# MSS_CTRL register map
Vendor: Texas Instruments
Peripheral module from a debugger description file (folder awr2544).
Registers are 32-bit, read-write, no defined reset value unless marked. A register's access mark holds for its fields unless they carry their own. Offsets are as the file gives them; lines under a group give offsets from that group; [hi:lo] are bit positions; {n}, {i} and the like mark numbered series; 'fields as' and 'values as' point back to an identical list; <NAME> marks a mode.

## MSS_CTRL (part 1 of 2)
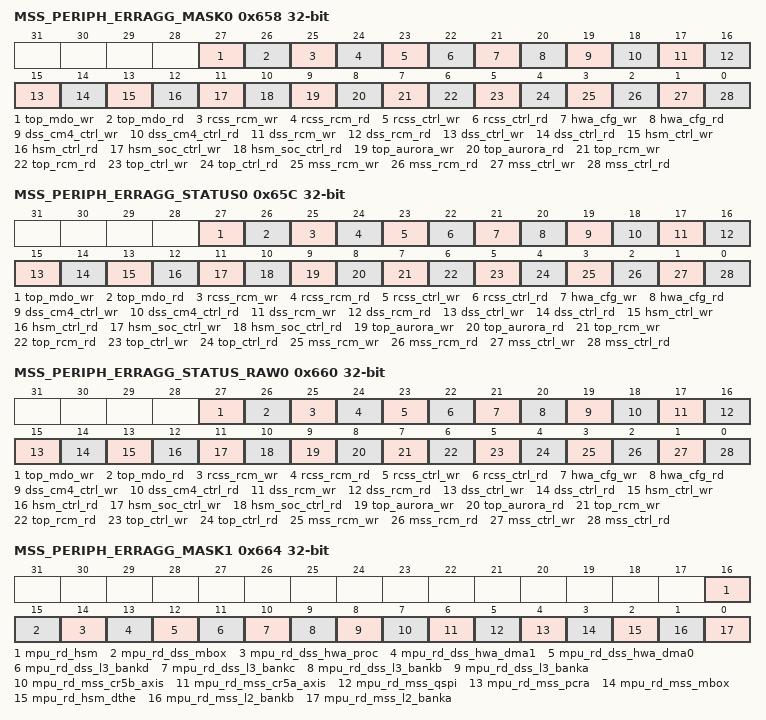
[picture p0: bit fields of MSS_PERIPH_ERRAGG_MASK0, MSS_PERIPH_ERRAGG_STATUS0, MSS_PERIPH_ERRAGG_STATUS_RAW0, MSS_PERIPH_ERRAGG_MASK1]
0x658 MSS_PERIPH_ERRAGG_MASK0
  [27] top_mdo_wr — RESERVED:Dont Use
  [26] top_mdo_rd — RESERVED:Dont Use
  [25] rcss_rcm_wr — Mask Interrupt from RSS_RCM to aggregated Interrupt MSS_PERIPH_ACCESS_ERRAGG 1 : Interrupt is Masked 0 : Interrupt is Unmasked
  [24] rcss_rcm_rd — Mask Interrupt from RSS_RCM to aggregated Interrupt MSS_PERIPH_ACCESS_ERRAGG 1 : Interrupt is Masked 0 : Interrupt is Unmasked
  [23] rcss_ctrl_wr — Mask Interrupt from RSS_CTRL to aggregated Interrupt MSS_PERIPH_ACCESS_ERRAGG 1 : Interrupt is Masked 0 : Interrupt is Unmasked
  [22] rcss_ctrl_rd — Mask Interrupt from RSS_CTRL to aggregated Interrupt MSS_PERIPH_ACCESS_ERRAGG 1 : Interrupt is Masked 0 : Interrupt is Unmasked
  [21] hwa_cfg_wr — Mask Interrupt from HWA_CFG to aggregated Interrupt MSS_PERIPH_ACCESS_ERRAGG 1 : Interrupt is Masked 0 : Interrupt is Unmasked
  [20] hwa_cfg_rd — Mask Interrupt from HWA_CFG to aggregated Interrupt MSS_PERIPH_ACCESS_ERRAGG 1 : Interrupt is Masked 0 : Interrupt is Unmasked
  [19] dss_cm4_ctrl_wr — RESERVED:Dont Use
  [18] dss_cm4_ctrl_rd — RESERVED:Dont Use
  [17] dss_rcm_wr — Mask Interrupt from DSS_RCM to aggregated Interrupt MSS_PERIPH_ACCESS_ERRAGG 1 : Interrupt is Masked 0 : Interrupt is Unmasked
  [16] dss_rcm_rd — Mask Interrupt from DSS_RCM to aggregated Interrupt MSS_PERIPH_ACCESS_ERRAGG 1 : Interrupt is Masked 0 : Interrupt is Unmasked
  [15] dss_ctrl_wr — Mask Interrupt from DSS_CTRL to aggregated Interrupt MSS_PERIPH_ACCESS_ERRAGG 1 : Interrupt is Masked 0 : Interrupt is Unmasked
  [14] dss_ctrl_rd — Mask Interrupt from DSS_CTRL to aggregated Interrupt MSS_PERIPH_ACCESS_ERRAGG 1 : Interrupt is Masked 0 : Interrupt is Unmasked
  [13] hsm_ctrl_wr — Mask Interrupt from HSM_CTRL to aggregated Interrupt MSS_PERIPH_ACCESS_ERRAGG 1 : Interrupt is Masked 0 : Interrupt is Unmasked
  [12] hsm_ctrl_rd — Mask Interrupt from HSM_CTRL to aggregated Interrupt MSS_PERIPH_ACCESS_ERRAGG 1 : Interrupt is Masked 0 : Interrupt is Unmasked
  [11] hsm_soc_ctrl_wr — Mask Interrupt from HSM_SOC_CTRL to aggregated Interrupt MSS_PERIPH_ACCESS_ERRAGG 1 : Interrupt is Masked 0 : Interrupt is Unmasked
  [10] hsm_soc_ctrl_rd — Mask Interrupt from HSM_SOC_CTRL to aggregated Interrupt MSS_PERIPH_ACCESS_ERRAGG 1 : Interrupt is Masked 0 : Interrupt is Unmasked
  [9] top_aurora_wr — RESERVED:Dont Use
  [8] top_aurora_rd — RESERVED:Dont Use
  [7] top_rcm_wr — Mask Interrupt from TOP_RCM to aggregated Interrupt MSS_PERIPH_ACCESS_ERRAGG 1 : Interrupt is Masked 0 : Interrupt is Unmasked
  [6] top_rcm_rd — Mask Interrupt from TOP_RCM to aggregated Interrupt MSS_PERIPH_ACCESS_ERRAGG 1 : Interrupt is Masked 0 : Interrupt is Unmasked
  [5] top_ctrl_wr — Mask Interrupt from TOP_CTRL to aggregated Interrupt MSS_PERIPH_ACCESS_ERRAGG 1 : Interrupt is Masked 0 : Interrupt is Unmasked
  [4] top_ctrl_rd — Mask Interrupt from TOP_CTRL to aggregated Interrupt MSS_PERIPH_ACCESS_ERRAGG 1 : Interrupt is Masked 0 : Interrupt is Unmasked
  [3] mss_rcm_wr — Mask Interrupt from MSS_RCM to aggregated Interrupt MSS_PERIPH_ACCESS_ERRAGG 1 : Interrupt is Masked 0 : Interrupt is Unmasked
  [2] mss_rcm_rd — Mask Interrupt from MSS_RCM to aggregated Interrupt MSS_PERIPH_ACCESS_ERRAGG 1 : Interrupt is Masked 0 : Interrupt is Unmasked
  [1] mss_ctrl_wr — Mask Interrupt from MSS_CTRL to aggregated Interrupt MSS_PERIPH_ACCESS_ERRAGG 1 : Interrupt is Masked 0 : Interrupt is Unmasked
  [0] mss_ctrl_rd — Mask Interrupt from MSS_CTRL to aggregated Interrupt MSS_PERIPH_ACCESS_ERRAGG 1 : Interrupt is Masked 0 : Interrupt is Unmasked
0x65C MSS_PERIPH_ERRAGG_STATUS0
  [27] top_mdo_wr — RESERVED:Dont Use
  [26] top_mdo_rd — RESERVED:Dont Use
  [25] rcss_rcm_wr — Status of Interrupt from RSS_RCM Set only if Interupt is unmasked in MSS_PERIPH_ERRAGG_MASK0 Wrie 0x1 to clear this interrupt.
  [24] rcss_rcm_rd — Status of Interrupt from RSS_RCM Set only if Interupt is unmasked in MSS_PERIPH_ERRAGG_MASK0 Wrie 0x1 to clear this interrupt.
  [23] rcss_ctrl_wr — Status of Interrupt from RSS_CTRL Set only if Interupt is unmasked in MSS_PERIPH_ERRAGG_MASK0 Wrie 0x1 to clear this interrupt.
  [22] rcss_ctrl_rd — Status of Interrupt from RSS_CTRL Set only if Interupt is unmasked in MSS_PERIPH_ERRAGG_MASK0 Wrie 0x1 to clear this interrupt.
  [21] hwa_cfg_wr — Status of Interrupt from HWA_CFG Set only if Interupt is unmasked in MSS_PERIPH_ERRAGG_MASK0 Wrie 0x1 to clear this interrupt.
  [20] hwa_cfg_rd — Status of Interrupt from HWA_CFG Set only if Interupt is unmasked in MSS_PERIPH_ERRAGG_MASK0 Wrie 0x1 to clear this interrupt.
  [19] dss_cm4_ctrl_wr — RESERVED:Dont Use
  [18] dss_cm4_ctrl_rd — RESERVED:Dont Use
  [17] dss_rcm_wr — Status of Interrupt from DSS_RCM Set only if Interupt is unmasked in MSS_PERIPH_ERRAGG_MASK0 Wrie 0x1 to clear this interrupt.
  [16] dss_rcm_rd — Status of Interrupt from DSS_RCM Set only if Interupt is unmasked in MSS_PERIPH_ERRAGG_MASK0 Wrie 0x1 to clear this interrupt.
  [15] dss_ctrl_wr — Status of Interrupt from DSS_CTRL Set only if Interupt is unmasked in MSS_PERIPH_ERRAGG_MASK0 Wrie 0x1 to clear this interrupt.
  [14] dss_ctrl_rd — Status of Interrupt from DSS_CTRL Set only if Interupt is unmasked in MSS_PERIPH_ERRAGG_MASK0 Wrie 0x1 to clear this interrupt.
  [13] hsm_ctrl_wr — Status of Interrupt from HSM_CTRL Set only if Interupt is unmasked in MSS_PERIPH_ERRAGG_MASK0 Wrie 0x1 to clear this interrupt.
  [12] hsm_ctrl_rd — Status of Interrupt from HSM_CTRL Set only if Interupt is unmasked in MSS_PERIPH_ERRAGG_MASK0 Wrie 0x1 to clear this interrupt.
  [11] hsm_soc_ctrl_wr — Status of Interrupt from HSM_SOC_CTRL Set only if Interupt is unmasked in MSS_PERIPH_ERRAGG_MASK0 Wrie 0x1 to clear this interrupt.
  [10] hsm_soc_ctrl_rd — Status of Interrupt from HSM_SOC_CTRL Set only if Interupt is unmasked in MSS_PERIPH_ERRAGG_MASK0 Wrie 0x1 to clear this interrupt.
  [9] top_aurora_wr — RESERVED:Dont Use
  [8] top_aurora_rd — RESERVED:Dont Use
  [7] top_rcm_wr — Status of Interrupt from TOP_RCM Set only if Interupt is unmasked in MSS_PERIPH_ERRAGG_MASK0 Wrie 0x1 to clear this interrupt.
  [6] top_rcm_rd — Status of Interrupt from TOP_RCM Set only if Interupt is unmasked in MSS_PERIPH_ERRAGG_MASK0 Wrie 0x1 to clear this interrupt.
  [5] top_ctrl_wr — Status of Interrupt from TOP_CTRL Set only if Interupt is unmasked in MSS_PERIPH_ERRAGG_MASK0 Wrie 0x1 to clear this interrupt.
  [4] top_ctrl_rd — Status of Interrupt from TOP_CTRL Set only if Interupt is unmasked in MSS_PERIPH_ERRAGG_MASK0 Wrie 0x1 to clear this interrupt.
  [3] mss_rcm_wr — Status of Interrupt from MSS_RCM Set only if Interupt is unmasked in MSS_PERIPH_ERRAGG_MASK0 Wrie 0x1 to clear this interrupt.
  [2] mss_rcm_rd — Status of Interrupt from MSS_RCM Set only if Interupt is unmasked in MSS_PERIPH_ERRAGG_MASK0 Wrie 0x1 to clear this interrupt.
  [1] mss_ctrl_wr — Status of Interrupt from MSS_CTRL Set only if Interupt is unmasked in MSS_PERIPH_ERRAGG_MASK0 Wrie 0x1 to clear this interrupt.
  [0] mss_ctrl_rd — Status of Interrupt from MSS_CTRL Set only if Interupt is unmasked in MSS_PERIPH_ERRAGG_MASK0 Wrie 0x1 to clear this interrupt.
0x660 MSS_PERIPH_ERRAGG_STATUS_RAW0
  [27] top_mdo_wr — RESERVED:Dont Use
  [26] top_mdo_rd — RESERVED:Dont Use
  [25] rcss_rcm_wr — Raw Status of Interrupt from RSS_RCM. Set irrespective if the Interupt is masked or unmasked in MSS_PERIPH_ERRAGG_MASK0
  [24] rcss_rcm_rd — Raw Status of Interrupt from RSS_RCM. Set irrespective if the Interupt is masked or unmasked in MSS_PERIPH_ERRAGG_MASK0
  [23] rcss_ctrl_wr — Raw Status of Interrupt from RSS_CTRL. Set irrespective if the Interupt is masked or unmasked in MSS_PERIPH_ERRAGG_MASK0
  [22] rcss_ctrl_rd — Raw Status of Interrupt from RSS_CTRL. Set irrespective if the Interupt is masked or unmasked in MSS_PERIPH_ERRAGG_MASK0
  [21] hwa_cfg_wr — Raw Status of Interrupt from HWA_CFG. Set irrespective if the Interupt is masked or unmasked in MSS_PERIPH_ERRAGG_MASK0
  [20] hwa_cfg_rd — Raw Status of Interrupt from HWA_CFG. Set irrespective if the Interupt is masked or unmasked in MSS_PERIPH_ERRAGG_MASK0
  [19] dss_cm4_ctrl_wr — RESERVED:Dont Use
  [18] dss_cm4_ctrl_rd — RESERVED:Dont Use
  [17] dss_rcm_wr — Raw Status of Interrupt from DSS_RCM. Set irrespective if the Interupt is masked or unmasked in MSS_PERIPH_ERRAGG_MASK0
  [16] dss_rcm_rd — Raw Status of Interrupt from DSS_RCM. Set irrespective if the Interupt is masked or unmasked in MSS_PERIPH_ERRAGG_MASK0
  [15] dss_ctrl_wr — Raw Status of Interrupt from DSS_CTRL. Set irrespective if the Interupt is masked or unmasked in MSS_PERIPH_ERRAGG_MASK0
  [14] dss_ctrl_rd — Raw Status of Interrupt from DSS_CTRL. Set irrespective if the Interupt is masked or unmasked in MSS_PERIPH_ERRAGG_MASK0
  [13] hsm_ctrl_wr — Raw Status of Interrupt from HSM_CTRL. Set irrespective if the Interupt is masked or unmasked in MSS_PERIPH_ERRAGG_MASK0
  [12] hsm_ctrl_rd — Raw Status of Interrupt from HSM_CTRL. Set irrespective if the Interupt is masked or unmasked in MSS_PERIPH_ERRAGG_MASK0
  [11] hsm_soc_ctrl_wr — Raw Status of Interrupt from HSM_SOC_CTRL. Set irrespective if the Interupt is masked or unmasked in MSS_PERIPH_ERRAGG_MASK0
  [10] hsm_soc_ctrl_rd — Raw Status of Interrupt from HSM_SOC_CTRL. Set irrespective if the Interupt is masked or unmasked in MSS_PERIPH_ERRAGG_MASK0
  [9] top_aurora_wr — RESERVED:Dont Use
  [8] top_aurora_rd — RESERVED:Dont Use
  [7] top_rcm_wr — Raw Status of Interrupt from TOP_RCM. Set irrespective if the Interupt is masked or unmasked in MSS_PERIPH_ERRAGG_MASK0
  [6] top_rcm_rd — Raw Status of Interrupt from TOP_RCM. Set irrespective if the Interupt is masked or unmasked in MSS_PERIPH_ERRAGG_MASK0
  [5] top_ctrl_wr — Raw Status of Interrupt from TOP_CTRL. Set irrespective if the Interupt is masked or unmasked in MSS_PERIPH_ERRAGG_MASK0
  [4] top_ctrl_rd — Raw Status of Interrupt from TOP_CTRL. Set irrespective if the Interupt is masked or unmasked in MSS_PERIPH_ERRAGG_MASK0
  [3] mss_rcm_wr — Raw Status of Interrupt from MSS_RCM. Set irrespective if the Interupt is masked or unmasked in MSS_PERIPH_ERRAGG_MASK0
  [2] mss_rcm_rd — Raw Status of Interrupt from MSS_RCM. Set irrespective if the Interupt is masked or unmasked in MSS_PERIPH_ERRAGG_MASK0
  [1] mss_ctrl_wr — Raw Status of Interrupt from MSS_CTRL. Set irrespective if the Interupt is masked or unmasked in MSS_PERIPH_ERRAGG_MASK0
  [0] mss_ctrl_rd — Raw Status of Interrupt from MSS_CTRL. Set irrespective if the Interupt is masked or unmasked in MSS_PERIPH_ERRAGG_MASK0
0x664 MSS_PERIPH_ERRAGG_MASK1
  [16] mpu_rd_hsm — Mask Interrupt from MPU_DSS_HSM to aggregated Interrupt MSS_PERIPH_ACCESS_ERRAGG 1 : Interrupt is Masked 0 : Interrupt is Unmasked
  [15] mpu_rd_dss_mbox — Mask Interrupt from MPU_DSS_MBOX to aggregated Interrupt MSS_PERIPH_ACCESS_ERRAGG 1 : Interrupt is Masked 0 : Interrupt is Unmasked
  [14] mpu_rd_dss_hwa_proc — RESERVED:Dont Use
  [13] mpu_rd_dss_hwa_dma1 — MRESERVED:Dont Use
  [12] mpu_rd_dss_hwa_dma0 — RESERVED:Dont Use
  [11] mpu_rd_dss_l3_bankd — RESERVED:Dont Use
  [10] mpu_rd_dss_l3_bankc — RESERVED:Dont Use
  [9] mpu_rd_dss_l3_bankb — Mask Interrupt from MPU_DSS_L3_BANKB to aggregated Interrupt MSS_PERIPH_ACCESS_ERRAGG 1 : Interrupt is Masked 0 : Interrupt is Unmasked
  [8] mpu_rd_dss_l3_banka — Mask Interrupt from MPU_DSS_L3_BANKA to aggregated Interrupt MSS_PERIPH_ACCESS_ERRAGG 1 : Interrupt is Masked 0 : Interrupt is Unmasked
  [7] mpu_rd_mss_cr5b_axis — Mask Interrupt from MPU_MSS_L2_BANKC to aggregated Interrupt MSS_PERIPH_ACCESS_ERRAGG 1 : Interrupt is Masked 0 : Interrupt is Unmasked
  [6] mpu_rd_mss_cr5a_axis — Mask Interrupt from MPU_MSS_CR5A_AXIS to aggregated Interrupt MSS_PERIPH_ACCESS_ERRAGG 1 : Interrupt is Masked 0 : Interrupt is Unmasked
  [5] mpu_rd_mss_qspi — Mask Interrupt from MPU_MSS_QSPI to aggregated Interrupt MSS_PERIPH_ACCESS_ERRAGG 1 : Interrupt is Masked 0 : Interrupt is Unmasked
  [4] mpu_rd_mss_pcra — Mask Interrupt from MPU_MSS_PCRA to aggregated Interrupt MSS_PERIPH_ACCESS_ERRAGG 1 : Interrupt is Masked 0 : Interrupt is Unmasked
  [3] mpu_rd_mss_mbox — Mask Interrupt from MPU_MSS_MBOX to aggregated Interrupt MSS_PERIPH_ACCESS_ERRAGG 1 : Interrupt is Masked 0 : Interrupt is Unmasked
  [2] mpu_rd_hsm_dthe — Mask Interrupt from MPU_HSM_DTHE to aggregated Interrupt MSS_PERIPH_ACCESS_ERRAGG 1 : Interrupt is Masked 0 : Interrupt is Unmasked
  [1] mpu_rd_mss_l2_bankb — Mask Interrupt from MPU_MSS_L2_BANKB to aggregated Interrupt MSS_PERIPH_ACCESS_ERRAGG 1 : Interrupt is Masked 0 : Interrupt is Unmasked
  [0] mpu_rd_mss_l2_banka — Mask Interrupt from MPU_MSS_L2_BANKA to aggregated Interrupt MSS_PERIPH_ACCESS_ERRAGG 1 : Interrupt is Masked 0 : Interrupt is Unmasked
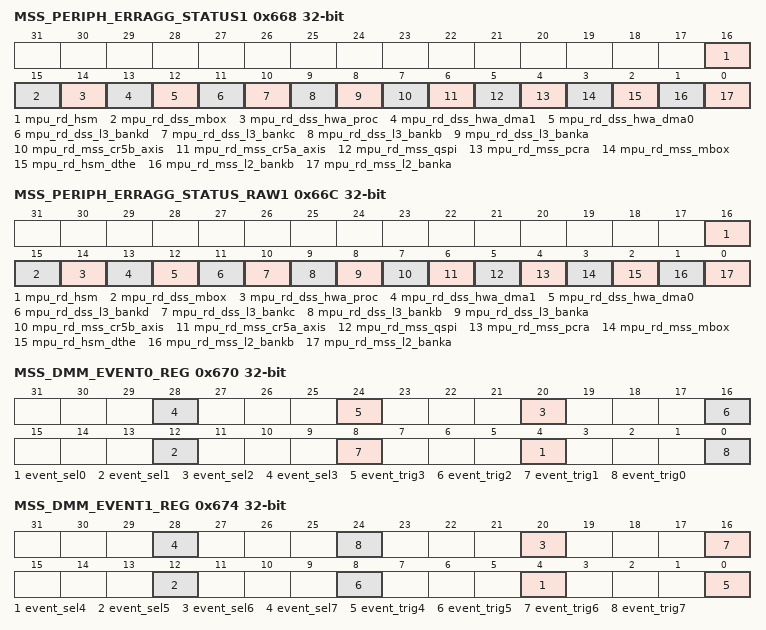
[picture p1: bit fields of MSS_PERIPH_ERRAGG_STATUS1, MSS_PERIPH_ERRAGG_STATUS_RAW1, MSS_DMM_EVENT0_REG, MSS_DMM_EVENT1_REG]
0x668 MSS_PERIPH_ERRAGG_STATUS1
  [16] mpu_rd_hsm — Status of Interrupt from MPU_HSM Set only if Interupt is unmasked in MSS_PERIPH_ERRAGG_MASK1 Wrie 0x1 to clear this interrupt.
  [15] mpu_rd_dss_mbox — Status of Interrupt from MPU_DSS_MBOX Set only if Interupt is unmasked in MSS_PERIPH_ERRAGG_MASK1 Wrie 0x1 to clear this interrupt.
  [14] mpu_rd_dss_hwa_proc — RESERVED:Dont Use
  [13] mpu_rd_dss_hwa_dma1 — RESERVED:Dont Use
  [12] mpu_rd_dss_hwa_dma0 — RESERVED:Dont Use
  [11] mpu_rd_dss_l3_bankd — RESERVED:Dont Use
  [10] mpu_rd_dss_l3_bankc — RESERVED:Dont Use
  [9] mpu_rd_dss_l3_bankb — Status of Interrupt from MPU_DSS_L3_BANKB Set only if Interupt is unmasked in MSS_PERIPH_ERRAGG_MASK1 Wrie 0x1 to clear this interrupt.
  [8] mpu_rd_dss_l3_banka — Status of Interrupt from MPU_DSS_L3_BANKA Set only if Interupt is unmasked in MSS_PERIPH_ERRAGG_MASK1 Wrie 0x1 to clear this interrupt.
  [7] mpu_rd_mss_cr5b_axis — Status of Interrupt from MPU_MSS_L2_BANKC Set only if Interupt is unmasked in MSS_PERIPH_ERRAGG_MASK1 Wrie 0x1 to clear this interrupt.
  [6] mpu_rd_mss_cr5a_axis — Status of Interrupt from MPU_MSS_CR5A_AXIS Set only if Interupt is unmasked in MSS_PERIPH_ERRAGG_MASK1 Wrie 0x1 to clear this interrupt.
  [5] mpu_rd_mss_qspi — Status of Interrupt from MPU_MSS_QSPI Set only if Interupt is unmasked in MSS_PERIPH_ERRAGG_MASK1 Wrie 0x1 to clear this interrupt.
  [4] mpu_rd_mss_pcra — Status of Interrupt from MPU_MSS_PCRA Set only if Interupt is unmasked in MSS_PERIPH_ERRAGG_MASK1 Wrie 0x1 to clear this interrupt.
  [3] mpu_rd_mss_mbox — Status of Interrupt from MPU_MSS_MBOX Set only if Interupt is unmasked in MSS_PERIPH_ERRAGG_MASK1 Wrie 0x1 to clear this interrupt.
  [2] mpu_rd_hsm_dthe — Status of Interrupt from MPU_HSM_DTHE Set only if Interupt is unmasked in MSS_PERIPH_ERRAGG_MASK1 Wrie 0x1 to clear this interrupt.
  [1] mpu_rd_mss_l2_bankb — Status of Interrupt from MPU_MSS_L2_BANKB Set only if Interupt is unmasked in MSS_PERIPH_ERRAGG_MASK1 Wrie 0x1 to clear this interrupt.
  [0] mpu_rd_mss_l2_banka — Status of Interrupt from MPU_MSS_L2_BANKA Set only if Interupt is unmasked in MSS_PERIPH_ERRAGG_MASK1 Wrie 0x1 to clear this interrupt.
0x66C MSS_PERIPH_ERRAGG_STATUS_RAW1
  [16] mpu_rd_hsm — Raw Status of Interrupt from MPU_HSM. Set irrespective if the Interupt is masked or unmasked in MSS_PERIPH_ERRAGG_MASK1
  [15] mpu_rd_dss_mbox — Raw Status of Interrupt from MPU_DSS_MBOX. Set irrespective if the Interupt is masked or unmasked in MSS_PERIPH_ERRAGG_MASK1
  [14] mpu_rd_dss_hwa_proc — RESERVED:Dont Use
  [13] mpu_rd_dss_hwa_dma1 — RESERVED:Dont Use
  [12] mpu_rd_dss_hwa_dma0 — RESERVED:Dont Use
  [11] mpu_rd_dss_l3_bankd — RESERVED:Dont Use
  [10] mpu_rd_dss_l3_bankc — RESERVED:Dont Use
  [9] mpu_rd_dss_l3_bankb — Raw Status of Interrupt from MPU_DSS_L3_BANKB. Set irrespective if the Interupt is masked or unmasked in MSS_PERIPH_ERRAGG_MASK1
  [8] mpu_rd_dss_l3_banka — Raw Status of Interrupt from MPU_DSS_L3_BANKA. Set irrespective if the Interupt is masked or unmasked in MSS_PERIPH_ERRAGG_MASK1
  [7] mpu_rd_mss_cr5b_axis — Raw Status of Interrupt from MPU_MSS_L2_BANKC. Set irrespective if the Interupt is masked or unmasked in MSS_PERIPH_ERRAGG_MASK1
  [6] mpu_rd_mss_cr5a_axis — Raw Status of Interrupt from MPU_MSS_CR5A_AXIS. Set irrespective if the Interupt is masked or unmasked in MSS_PERIPH_ERRAGG_MASK1
  [5] mpu_rd_mss_qspi — Raw Status of Interrupt from MPU_MSS_QSPI. Set irrespective if the Interupt is masked or unmasked in MSS_PERIPH_ERRAGG_MASK1
  [4] mpu_rd_mss_pcra — Raw Status of Interrupt from MPU_MSS_PCRA. Set irrespective if the Interupt is masked or unmasked in MSS_PERIPH_ERRAGG_MASK1
  [3] mpu_rd_mss_mbox — Raw Status of Interrupt from MPU_MSS_MBOX. Set irrespective if the Interupt is masked or unmasked in MSS_PERIPH_ERRAGG_MASK1
  [2] mpu_rd_hsm_dthe — Raw Status of Interrupt from MPU_HSM_DTHE. Set irrespective if the Interupt is masked or unmasked in MSS_PERIPH_ERRAGG_MASK1
  [1] mpu_rd_mss_l2_bankb — Raw Status of Interrupt from MPU_MSS_L2_BANKB. Set irrespective if the Interupt is masked or unmasked in MSS_PERIPH_ERRAGG_MASK1
  [0] mpu_rd_mss_l2_banka — Raw Status of Interrupt from MPU_MSS_L2_BANKA. Set irrespective if the Interupt is masked or unmasked in MSS_PERIPH_ERRAGG_MASK1
0x670 MSS_DMM_EVENT0_REG
  [8n+4] event_sel{n} (n=0..3) — Writing 1'b1 : Selects DMM event_trig as interrupt source. 1'b0 : Selects actual interrupt as interrupt source.
  [24] event_trig3 — DMM trigger for RSS_CSI2A_EOL_CNTX1_INT
  [16] event_trig2 — DMM trigger for RSS_CSI2A_EOL_CNTX0_INT
  [8] event_trig1 — DMM trigger for RSS_CSI2A_SOF_INT1
  [0] event_trig0 — DMM trigger for RSS_CSI2A_SOF_INT0
0x674 MSS_DMM_EVENT1_REG
  [8n-28] event_sel{n} (n=4..7) — Writing 1'b1 : Selects DMM event_trig as interrupt source. 1'b0 : Selects actual interrupt as interrupt source.
  [8n-32] event_trig{n} (n=4..7) — DMM trigger for RSS_CSI2A_EOL_CNTX{n-2}_INT
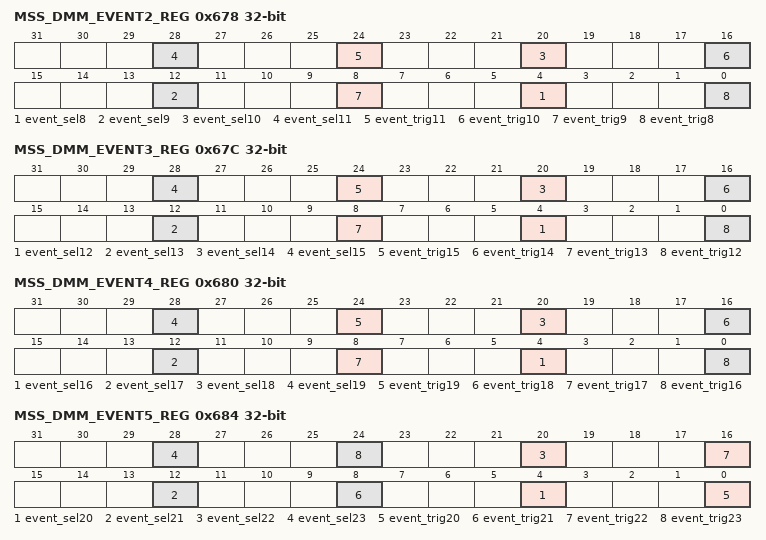
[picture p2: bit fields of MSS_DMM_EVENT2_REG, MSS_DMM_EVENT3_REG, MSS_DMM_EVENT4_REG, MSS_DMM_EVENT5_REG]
0x678 MSS_DMM_EVENT2_REG
  [8n-60] event_sel{n} (n=8..11) — Writing 1'b1 : Selects DMM event_trig as interrupt source. 1'b0 : Selects actual interrupt as interrupt source.
  [24] event_trig11 — DMM trigger for RSS_ADC_CAPTURE_COMPLETE (to DMA)
  [16] event_trig10 — DMM trigger for DFE_FRAME_START_TO_DSS
  [8] event_trig9 — DMM trigger for RSS_CSI2A_EOL_CNTX7_INT
  [0] event_trig8 — DMM trigger for RSS_CSI2A_EOL_CNTX6_INT
0x67C MSS_DMM_EVENT3_REG
  [8n-92] event_sel{n} (n=12..15) — Writing 1'b1 : Selects DMM event_trig as interrupt source. 1'b0 : Selects actual interrupt as interrupt source.
  [24] event_trig15 — DMM trigger for RSS_ADC_CAPTURE_COMPLETE (to interrupts)
  [16] event_trig14 — DMM trigger for FRC_LOGICAL_FRAME_END
  [8] event_trig13 — DMM trigger for FRC_LOGICAL_FRAME_START
  [0] event_trig12 — DMM trigger for RSS_DATA_CAPTURE_ENABLE_FALL
0x680 MSS_DMM_EVENT4_REG
  [8n-124] event_sel{n} (n=16..19) — Writing 1'b1 : Selects DMM event_trig as interrupt source. 1'b0 : Selects actual interrupt as interrupt source.
  [24] event_trig19 — DMM trigger Reserved
  [16] event_trig18 — DMM trigger Reserved
  [8] event_trig17 — DMM trigger Reserved
  [0] event_trig16 — DMM trigger for ADC_CLK_ENABLE_VALID
0x684 MSS_DMM_EVENT5_REG
  [8n-156] event_sel{n} (n=20..23) — Writing 1'b1 : Selects DMM event_trig as interrupt source. 1'b0 : Selects actual interrupt as interrupt source.
  [8n-160] event_trig{n} (n=20..23) — DMM trigger Reserved
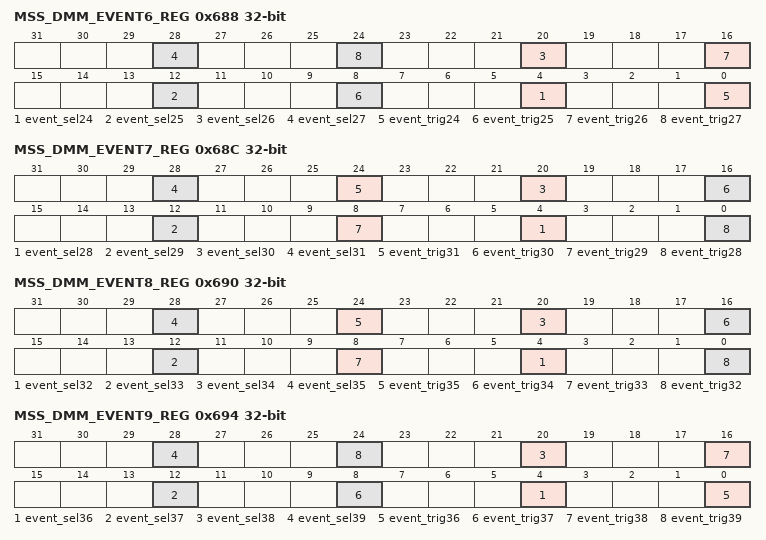
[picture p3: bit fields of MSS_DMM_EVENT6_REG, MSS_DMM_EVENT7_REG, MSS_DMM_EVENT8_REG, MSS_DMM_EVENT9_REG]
0x688 MSS_DMM_EVENT6_REG
  [8n-188] event_sel{n} (n=24..27) — Writing 1'b1 : Selects DMM event_trig as interrupt source. 1'b0 : Selects actual interrupt as interrupt source.
  [8n-192] event_trig{n} (n=24..27) — DMM trigger Reserved
0x68C MSS_DMM_EVENT7_REG
  [8n-220] event_sel{n} (n=28..31) — Writing 1'b1 : Selects DMM event_trig as interrupt source. 1'b0 : Selects actual interrupt as interrupt source.
  [24] event_trig31 — DMM trigger for DSS_HWA_THREAD1_PARAM_DONE
  [16] event_trig30 — DMM trigger for DSS_HWA_THREAD1_LOOP
  [8] event_trig29 — DMM trigger Reserved
  [0] event_trig28 — DMM trigger Reserved
0x690 MSS_DMM_EVENT8_REG
  [8n-252] event_sel{n} (n=32..35) — Writing 1'b1 : Selects DMM event_trig as interrupt source. 1'b0 : Selects actual interrupt as interrupt source.
  [24] event_trig35 — DMM trigger Reserved
  [16] event_trig34 — DMM trigger for DSS_HWA_LOCAL_RAM_ERR
  [8] event_trig33 — DMM trigger for DSS_HWA_THREAD2_PARAM_DONE
  [0] event_trig32 — DMM trigger for DSS_HWA_THREAD2_LOOP
0x694 MSS_DMM_EVENT9_REG
  [8n-284] event_sel{n} (n=36..39) — Writing 1'b1 : Selects DMM event_trig as interrupt source. 1'b0 : Selects actual interrupt as interrupt source.
  [8n-288] event_trig{n} (n=36..39) — DMM trigger Reserved
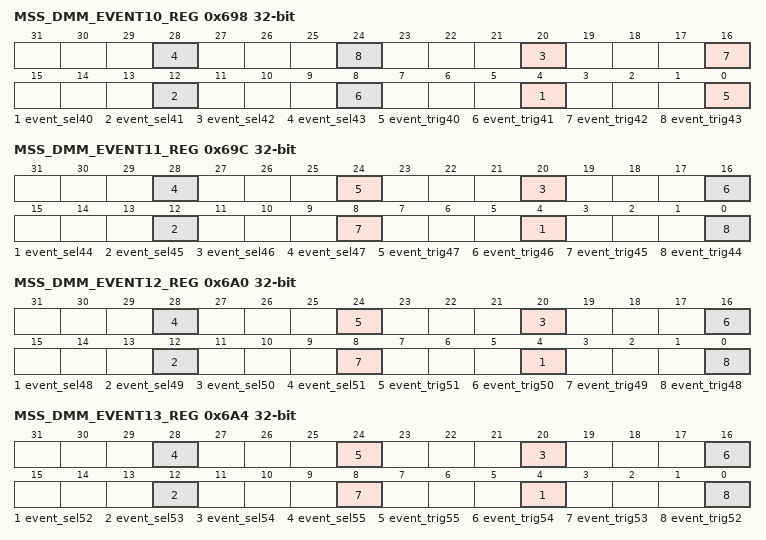
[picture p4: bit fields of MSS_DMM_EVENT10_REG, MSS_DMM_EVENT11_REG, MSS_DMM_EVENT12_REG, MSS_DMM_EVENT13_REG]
0x698 MSS_DMM_EVENT10_REG
  [8n-316] event_sel{n} (n=40..43) — Writing 1'b1 : Selects DMM event_trig as interrupt source. 1'b0 : Selects actual interrupt as interrupt source.
  [8n-320] event_trig{n} (n=40..43) — DMM trigger Reserved
0x69C MSS_DMM_EVENT11_REG
  [8n-348] event_sel{n} (n=44..47) — Writing 1'b1 : Selects DMM event_trig as interrupt source. 1'b0 : Selects actual interrupt as interrupt source.
  [24] event_trig47 — DMM trigger For MSS_MCANA_FE_INT source 2
  [16] event_trig46 — DMM trigger For MSS_MCANA_FE_INT source 1
  [8] event_trig45 — DMM trigger For MSS_MCANA_FE_INT source 0
  [0] event_trig44 — DMM trigger Reserved
0x6A0 MSS_DMM_EVENT12_REG
  [8n-380] event_sel{n} (n=48..51) — Writing 1'b1 : Selects DMM event_trig as interrupt source. 1'b0 : Selects actual interrupt as interrupt source.
  [24] event_trig51 — DMM trigger For MSS_MCANA_FE_INT source 1
  [16] event_trig50 — DMM trigger For MSS_MCANA_FE_INT source 0
  [8] event_trig49 — DMM trigger For MSS_MCANA_INT1
  [0] event_trig48 — DMM trigger For MSS_MCANA_INT0
0x6A4 MSS_DMM_EVENT13_REG
  [8n-412] event_sel{n} (n=52..55) — Writing 1'b1 : Selects DMM event_trig as interrupt source. 1'b0 : Selects actual interrupt as interrupt source.
  [24] event_trig55 — DMM trigger Reserved
  [16] event_trig54 — DMM trigger For MSS_MCANB_INT1
  [8] event_trig53 — DMM trigger For MSS_MCANB_INT0
  [0] event_trig52 — DMM trigger For MSS_MCANA_FE_INT source 2
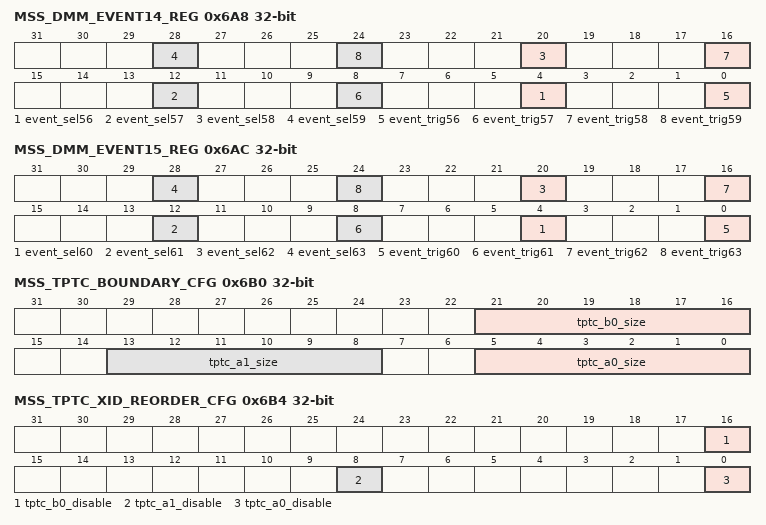
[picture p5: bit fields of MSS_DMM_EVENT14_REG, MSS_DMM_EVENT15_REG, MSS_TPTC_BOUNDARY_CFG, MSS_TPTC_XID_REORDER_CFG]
0x6A8 MSS_DMM_EVENT14_REG
  [8n-444] event_sel{n} (n=56..59) — Writing 1'b1 : Selects DMM event_trig as interrupt source. 1'b0 : Selects actual interrupt as interrupt source.
  [8n-448] event_trig{n} (n=56..59) — DMM trigger Reserved
0x6AC MSS_DMM_EVENT15_REG
  [8n-476] event_sel{n} (n=60..63) — Writing 1'b1 : Selects DMM event_trig as interrupt source. 1'b0 : Selects actual interrupt as interrupt source.
  [8n-480] event_trig{n} (n=60..63) — DMM trigger Reserved
0x6B0 MSS_TPTC_BOUNDARY_CFG
  [21:16] tptc_b0_size — 6 bit signal used for deciding the boundary crossing size for CID-RID-SID reordering of MSS_TPTC_B0 Example: writing 6'd19 decidies boundary to be 2^19 i.e. 512 KB
  [13:8] tptc_a1_size — 6 bit signal used for deciding the boundary crossing size for CID-RID-SID reordering of MSS_TPTC_A1 Example: writing 6'd19 decidies boundary to be 2^19 i.e. 512 KB
  [5:0] tptc_a0_size — 6 bit signal used for deciding the boundary crossing size for CID-RID-SID reordering of MSS_TPTC_A0 Example: writing 6'd19 decidies boundary to be 2^19 i.e. 512 KB
0x6B4 MSS_TPTC_XID_REORDER_CFG
  [16] tptc_b0_disable — writing 1'b1 will disable the CID-RID-SID reodering feature for MSS_TPTC_B0
  [8] tptc_a1_disable — writing 1'b1 will disable the CID-RID-SID reodering feature for MSS_TPTC_A1
  [0] tptc_a0_disable — writing 1'b1 will disable the CID-RID-SID reodering feature for MSS_TPTC_A0
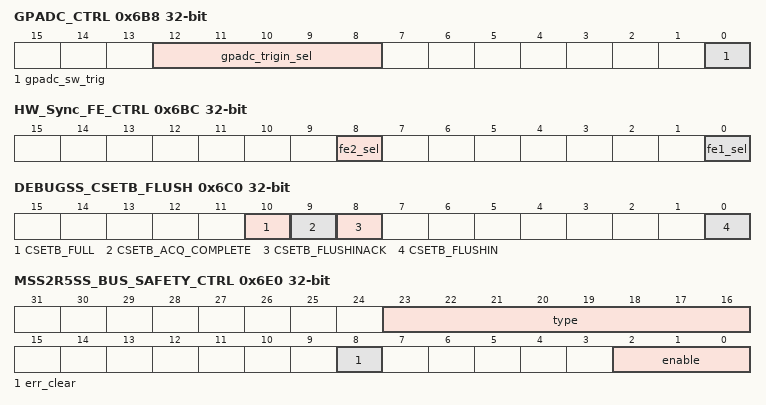
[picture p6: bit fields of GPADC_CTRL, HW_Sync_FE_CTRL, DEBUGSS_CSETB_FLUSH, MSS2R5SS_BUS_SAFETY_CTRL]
0x6B8 GPADC_CTRL
  [12:8] gpadc_trigin_sel — Writing below decimal values to this regiter will select corresponding interrupt as GPADC trigger source. 0: GPIO_0 1: GPIO_1 2: GPIO_2 3: GPIO_3 4: Reserved 5: Reserved 6: Reserved 7: Reserved 8: Reserved 9: Reseved 10: Reserved 11: MSS_RTIA_INT0 12: MSS_RTIA_INT1 13: HW_Sync_FE1 14: Reserved 15: MMR based SW trigger
  [0] gpadc_sw_trig — Writing 1'b1 will give MMR based SW trigger to GPADC
0x6BC HW_Sync_FE_CTRL
  [8] fe2_sel — Writing 1'b0 : Selects MCANA filter event as HW_Sync_FE2 1'b1 : Selects MCANB filter event as HW_Sync_FE2
  [0] fe1_sel — Writing 1'b0 : Selects MCANA filter event as HW_Sync_FE1 1'b1 : Selects MCANB filter event as HW_Sync_FE1
0x6C0 DEBUGSS_CSETB_FLUSH access per field
  [10] CSETB_FULL ro — When HIGH indicates that the ETB RAM has overflowed or wrapped around to address zero
  [9] CSETB_ACQ_COMPLETE ro — When HIGH, indicates that trace acquisition is complete by ETB, that is, the trigger counter is at zero
  [8] CSETB_FLUSHINACK ro — Return acknowledgement to CSETBFLUSHIN
  [0] CSETB_FLUSHIN rw — External control used to assert the ATB signal AFVALIDS and drain any historical FIFO information on the bus
0x6C4 ANALOG_WU_STATUS_REG_POLARITY_INV
  [31:0] inv_ctrl — This register decides the polarity of each status bit before providing to the MSS_ESM. Each bit controls the respective status bit.
0x6C8 ANALOG_CLK_STATUS_REG_POLARITY_INV
  fields as ANALOG_WU_STATUS_REG_POLARITY_INV
0x6CC ANALOG_WU_STATUS_REG_GRP1_MASK
  [31:0] mask — Writing 1'b1 : Masks the corresponding status bit before generating a group 1 ESM error. 1'b0 : Unmasks the corresponding status bit before generating a group 1 ESM error.
0x6D0 ANALOG_CLK_STATUS_REG_GRP1_MASK
  fields as ANALOG_WU_STATUS_REG_GRP1_MASK
0x6D4 ANALOG_WU_STATUS_REG_GRP2_MASK
  [31:0] mask — Writing 1'b1 : Masks the corresponding status bit before generating a group 2 ESM error. 1'b0 : Unmasks the corresponding status bit before generating a group 2 ESM error.
0x6D8 ANALOG_CLK_STATUS_REG_GRP2_MASK
  fields as ANALOG_WU_STATUS_REG_GRP2_MASK
0x6DC NERROR_MASK
  [2:0] mask — writing 3'b111 will mask the Nerror propagation to pad Writing 3'b000 will unmask the Nerror propagation to pad
0x6E0 MSS2R5SS_BUS_SAFETY_CTRL access per field
  [23:16] type ro — Refer to 25xx Substem Microarch document for more details
  [8] err_clear rw — Refer to 25xx Substem Microarch document for more details
  [2:0] enable rw — Refer to 25xx Substem Microarch document for more details
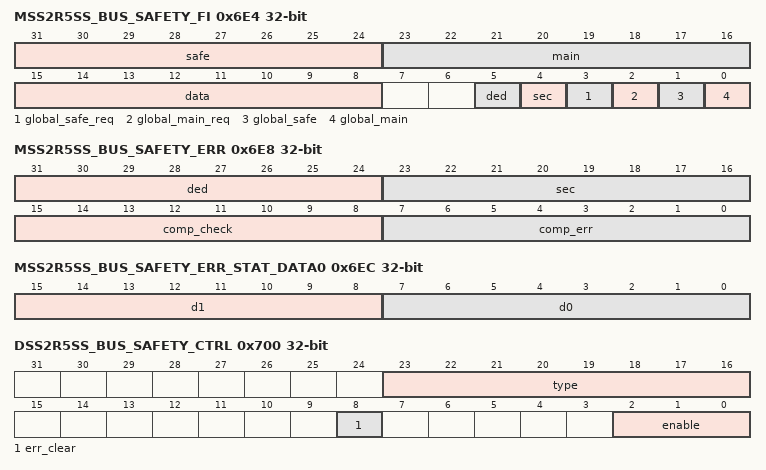
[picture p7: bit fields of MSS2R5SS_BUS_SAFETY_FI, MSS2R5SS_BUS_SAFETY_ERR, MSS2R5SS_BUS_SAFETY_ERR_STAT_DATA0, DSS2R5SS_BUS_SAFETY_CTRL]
0x6E4 MSS2R5SS_BUS_SAFETY_FI
  [31:24] safe — Refer to 25xx Substem Microarch document for more details
  [23:16] main — Refer to 25xx Substem Microarch document for more details
  [15:8] data — Refer to 25xx Substem Microarch document for more details
  [5] ded — Refer to 25xx Substem Microarch document for more details
  [4] sec — Refer to 25xx Substem Microarch document for more details
  [3] global_safe_req — Refer to 25xx Substem Microarch document for more details
  [2] global_main_req — Refer to 25xx Substem Microarch document for more details
  [1] global_safe — Refer to 25xx Substem Microarch document for more details
  [0] global_main — Refer to 25xx Substem Microarch document for more details
0x6E8 MSS2R5SS_BUS_SAFETY_ERR ro
  [31:24] ded — Refer to 25xx Substem Microarch document for more details
  [23:16] sec — Refer to 25xx Substem Microarch document for more details
  [15:8] comp_check — Refer to 25xx Substem Microarch document for more details
  [7:0] comp_err — Refer to 25xx Substem Microarch document for more details
0x6EC MSS2R5SS_BUS_SAFETY_ERR_STAT_DATA0 ro
  [15:8] d1 — Refer to 25xx Substem Microarch document for more details
  [7:0] d0 — Refer to 25xx Substem Microarch document for more details
0x6F0 MSS2R5SS_BUS_SAFETY_ERR_STAT_CMD ro
  [31:0] stat — Refer to 25xx Substem Microarch document for more details
0x6F4 MSS2R5SS_BUS_SAFETY_ERR_STAT_WRITE ro
  fields as MSS2R5SS_BUS_SAFETY_ERR_STAT_CMD
0x6F8 MSS2R5SS_BUS_SAFETY_ERR_STAT_READ ro
  fields as MSS2R5SS_BUS_SAFETY_ERR_STAT_CMD
0x6FC MSS2R5SS_BUS_SAFETY_ERR_STAT_WRITERESP ro
  fields as MSS2R5SS_BUS_SAFETY_ERR_STAT_CMD
0x700 DSS2R5SS_BUS_SAFETY_CTRL access per field
  fields as MSS2R5SS_BUS_SAFETY_CTRL
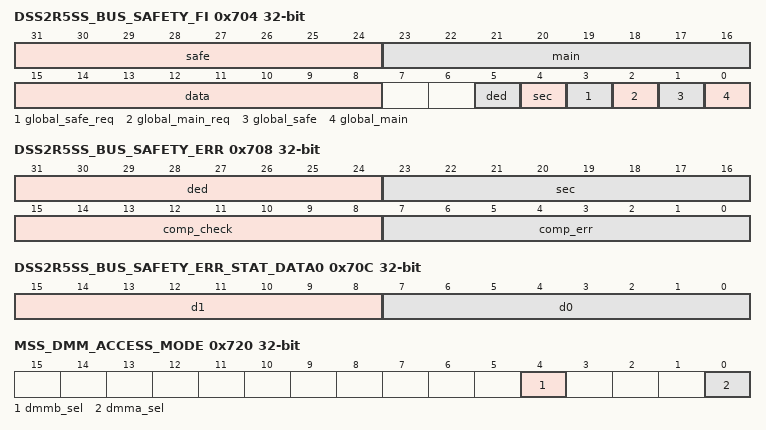
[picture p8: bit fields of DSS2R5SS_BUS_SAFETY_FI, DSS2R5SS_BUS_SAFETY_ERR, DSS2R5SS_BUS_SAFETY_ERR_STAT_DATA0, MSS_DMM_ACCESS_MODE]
0x704 DSS2R5SS_BUS_SAFETY_FI
  fields as MSS2R5SS_BUS_SAFETY_FI
0x708 DSS2R5SS_BUS_SAFETY_ERR ro
  fields as MSS2R5SS_BUS_SAFETY_ERR
0x70C DSS2R5SS_BUS_SAFETY_ERR_STAT_DATA0 ro
  fields as MSS2R5SS_BUS_SAFETY_ERR_STAT_DATA0
0x710 DSS2R5SS_BUS_SAFETY_ERR_STAT_CMD ro
  fields as MSS2R5SS_BUS_SAFETY_ERR_STAT_CMD
0x714 DSS2R5SS_BUS_SAFETY_ERR_STAT_WRITE ro
  fields as MSS2R5SS_BUS_SAFETY_ERR_STAT_CMD
0x718 DSS2R5SS_BUS_SAFETY_ERR_STAT_READ ro
  fields as MSS2R5SS_BUS_SAFETY_ERR_STAT_CMD
0x71C DSS2R5SS_BUS_SAFETY_ERR_STAT_WRITERESP ro
  fields as MSS2R5SS_BUS_SAFETY_ERR_STAT_CMD
0x720 MSS_DMM_ACCESS_MODE
  [4] dmmb_sel — writing 1'b0 : ensures all the accesses from DMMB are user-mode writing 1'b1 : ensures all the accesses from DMMB are privilege mode
  [0] dmma_sel — writing 1'b0 : ensures all the accesses from DMMA are user-mode writing 1'b1 : ensures all the accesses from DMMA are privilege mode
0x724 CPSW_HW_TRIG_CTRL
  [2:0] CPSW_HW_TRIG_CTRL — Bits [1:0] are used for Genf select line bits 2'b00 : Genf0 2'b01 : Genf1 2'b10 : Genf2 2'b11 : Not used Bit2 is used to select Genf or CPSW_HW_TRIG_VAL
0x728 CPSW_HW_TRIG_VAL
  [7:0] CPSW_HW_TRIG_VAL — Trigger
0x72C CPSW_TRIG_CAPTURE_COUNT
  [3:0] trig_count — Configuration of number of cycles for pulse extender of TRIG signal to CPSW
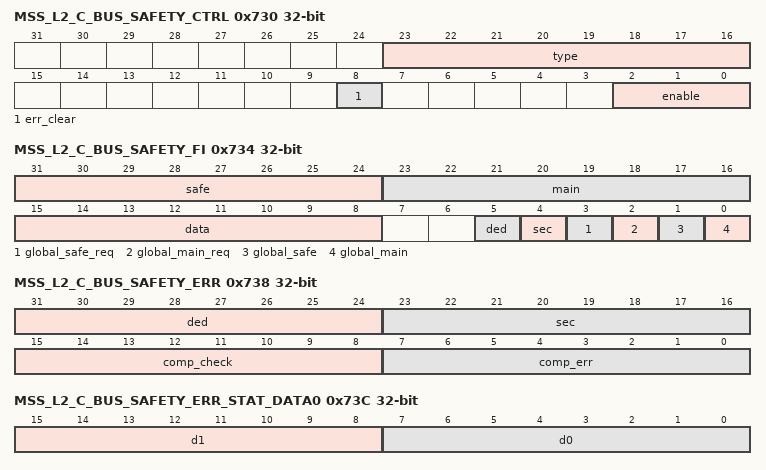
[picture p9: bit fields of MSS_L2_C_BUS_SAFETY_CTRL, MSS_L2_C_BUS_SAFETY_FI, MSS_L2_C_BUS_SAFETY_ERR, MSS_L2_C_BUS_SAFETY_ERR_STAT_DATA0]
0x730 MSS_L2_C_BUS_SAFETY_CTRL access per field
  fields as MSS2R5SS_BUS_SAFETY_CTRL
0x734 MSS_L2_C_BUS_SAFETY_FI
  fields as MSS2R5SS_BUS_SAFETY_FI
0x738 MSS_L2_C_BUS_SAFETY_ERR ro
  fields as MSS2R5SS_BUS_SAFETY_ERR
0x73C MSS_L2_C_BUS_SAFETY_ERR_STAT_DATA0 ro
  fields as MSS2R5SS_BUS_SAFETY_ERR_STAT_DATA0
0x740 MSS_L2_C_BUS_SAFETY_ERR_STAT_CMD ro
  fields as MSS2R5SS_BUS_SAFETY_ERR_STAT_CMD
0x744 MSS_L2_C_BUS_SAFETY_ERR_STAT_WRITE ro
  fields as MSS2R5SS_BUS_SAFETY_ERR_STAT_CMD
0x748 MSS_L2_C_BUS_SAFETY_ERR_STAT_READ ro
  fields as MSS2R5SS_BUS_SAFETY_ERR_STAT_CMD
0x74C MSS_L2_C_BUS_SAFETY_ERR_STAT_WRITERESP ro
  fields as MSS2R5SS_BUS_SAFETY_ERR_STAT_CMD
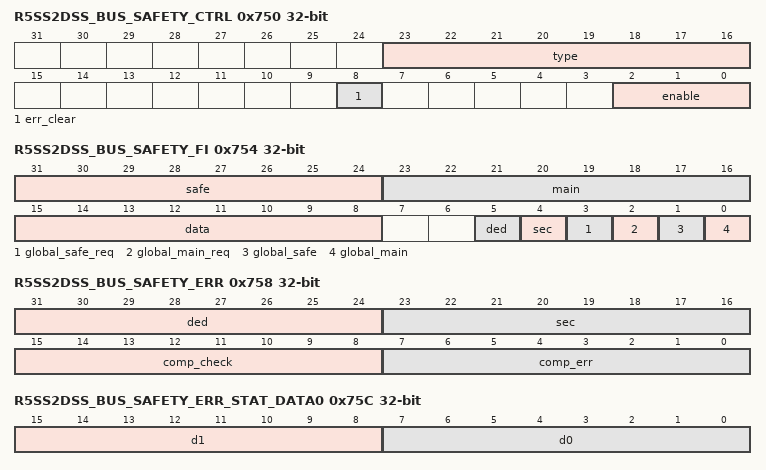
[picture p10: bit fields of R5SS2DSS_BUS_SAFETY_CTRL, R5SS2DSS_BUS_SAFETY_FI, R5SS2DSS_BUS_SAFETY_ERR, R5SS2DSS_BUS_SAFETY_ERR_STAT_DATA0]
0x750 R5SS2DSS_BUS_SAFETY_CTRL access per field
  fields as MSS2R5SS_BUS_SAFETY_CTRL
0x754 R5SS2DSS_BUS_SAFETY_FI
  fields as MSS2R5SS_BUS_SAFETY_FI
0x758 R5SS2DSS_BUS_SAFETY_ERR ro
  fields as MSS2R5SS_BUS_SAFETY_ERR
0x75C R5SS2DSS_BUS_SAFETY_ERR_STAT_DATA0 ro
  fields as MSS2R5SS_BUS_SAFETY_ERR_STAT_DATA0
0x760 R5SS2DSS_BUS_SAFETY_ERR_STAT_CMD ro
  fields as MSS2R5SS_BUS_SAFETY_ERR_STAT_CMD
0x764 R5SS2DSS_BUS_SAFETY_ERR_STAT_WRITE ro
  fields as MSS2R5SS_BUS_SAFETY_ERR_STAT_CMD
0x768 R5SS2DSS_BUS_SAFETY_ERR_STAT_READ ro
  fields as MSS2R5SS_BUS_SAFETY_ERR_STAT_CMD
0x76C R5SS2DSS_BUS_SAFETY_ERR_STAT_WRITERESP ro
  fields as MSS2R5SS_BUS_SAFETY_ERR_STAT_CMD
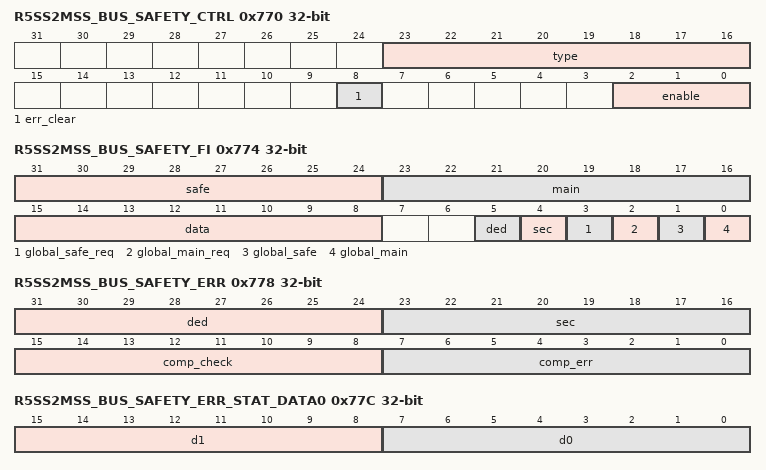
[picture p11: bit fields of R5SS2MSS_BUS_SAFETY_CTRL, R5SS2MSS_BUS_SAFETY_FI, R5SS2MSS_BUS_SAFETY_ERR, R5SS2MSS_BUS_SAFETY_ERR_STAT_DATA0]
0x770 R5SS2MSS_BUS_SAFETY_CTRL access per field
  fields as MSS2R5SS_BUS_SAFETY_CTRL
0x774 R5SS2MSS_BUS_SAFETY_FI
  fields as MSS2R5SS_BUS_SAFETY_FI
0x778 R5SS2MSS_BUS_SAFETY_ERR ro
  fields as MSS2R5SS_BUS_SAFETY_ERR
0x77C R5SS2MSS_BUS_SAFETY_ERR_STAT_DATA0 ro
  fields as MSS2R5SS_BUS_SAFETY_ERR_STAT_DATA0
0x780 R5SS2MSS_BUS_SAFETY_ERR_STAT_CMD ro
  fields as MSS2R5SS_BUS_SAFETY_ERR_STAT_CMD
0x784 R5SS2MSS_BUS_SAFETY_ERR_STAT_WRITE ro
  fields as MSS2R5SS_BUS_SAFETY_ERR_STAT_CMD
0x788 R5SS2MSS_BUS_SAFETY_ERR_STAT_READ ro
  fields as MSS2R5SS_BUS_SAFETY_ERR_STAT_CMD
0x78C R5SS2MSS_BUS_SAFETY_ERR_STAT_WRITERESP ro
  fields as MSS2R5SS_BUS_SAFETY_ERR_STAT_CMD
0x790 NW_PACKET_COUNT ro
  [31:0] stat — Gives the count of the ping-pong switch events of the network packet buffer
0x794 NW_PACKET_COUNT_RESET
  [0] undefined — Software reset for Counter maintaining Ping pong switch events
0x798 CPSW_CRC_PING_ADDR
  [15:0] undefined — This denotes the last address of the data Read. This depends on the Packet size . Example : If packet size is 3072 bytes or 3KB and CRC is disabled , this needs to programmed as 3064 or hBF8 If packet size is 3072 bytes or 3KB and 16 bit CRC , this needs to be programmed as hC00 Address must be 4 byte aligned for 32 bit CRC Address must be 2 byte aligned for 16 bit CRC
0x79C CPSW_CRC_PONG_ADDR
  fields as CPSW_CRC_PING_ADDR
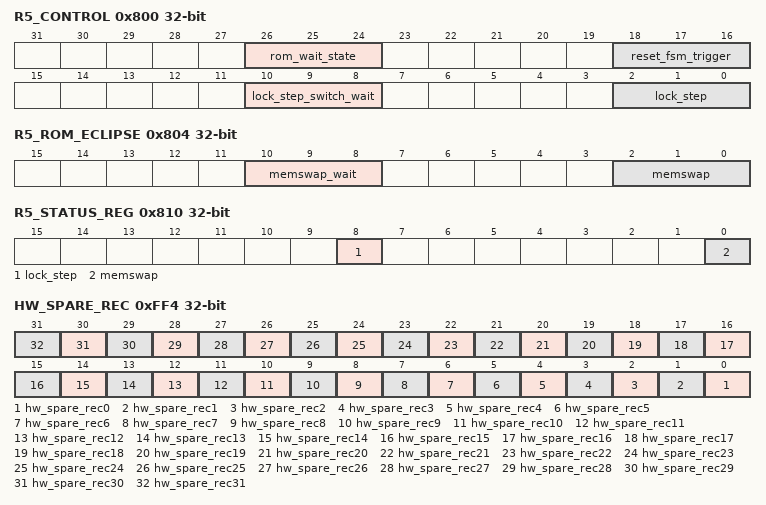
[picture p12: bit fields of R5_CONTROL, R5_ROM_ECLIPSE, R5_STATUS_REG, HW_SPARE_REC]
0x800 R5_CONTROL
  [26:24] rom_wait_state — writing '111' enables a single cycle wait state with respect to CR5A_clk for rom access. This needs to be set when R5 clock is at 400MHZ and Interconnect-clk is at 200MHZ. (because it is a timing issue in this scenario)
  [18:16] reset_fsm_trigger — Write pulse bit field: writing 3'b111 will trigger the reset FSM. Reset FSM ensures reset to R5SS and inturn ensures the latching of lock_step and also mem_swap bit
  [10:8] lock_step_switch_wait — writing 3'b111 ensures switch happens only after R5SS reset. Orelse it will be a immediate switch.
  [2:0] lock_step — writing 3'b000 ensures R5 to be in Dual-Core mode. Note: The change happens after the R5SS reset assertion if R5_CONTROL_lock_step_switch_wait is set. Or else the switiching to Dual-core happens on the fly.
0x804 R5_ROM_ECLIPSE
  [10:8] memswap_wait — writing 3'b111 ensures ROM-Eclipsing happens only after R5SS reset. Orelse it will be a immediate change.
  [2:0] memswap — writing '111' ensures eclipsing of CR5A_ROM immediately if memswap_wait is not set. If memswap_wait is set then ROM is eclipsed after R5SS reset assertion.
0x808 R5_COREA_HALT
  [2:0] halt — writing '000' will unhalt CR5A. This register should be written only once.
0x80C R5_COREB_HALT
  [2:0] halt — RESERVED: Dont Use
0x810 R5_STATUS_REG ro
  [8] lock_step — Reading 1: confirms R5SS is in lockstep mode. Reading 0: confirms R5SS is in Dual-core mode.
  [0] memswap — reading 1: confirms ROM is Eclipsed from with RAM for R5.
0xFD0 HW_SPARE_RW0
  [31:0] hw_spare_rw0 — [2:0] writing 3'b111 gates the clock to redundant-safe bridges and inteconnects [6:4] RESERVED [8]: Mux Select to RSS_Interrupt_Map to choose between Pbist_done and MSS_RTIC Interrupt [9]:writing 1'b1 clock-gates HSM hard-macro [31:7] Reserved for HW R&D
{0xFD0+4i} HW_SPARE_RW{i} (i=1..3)
  [31:0] hw_spare_rw{i} — Reserved for HW R&D
{0xFE0+4i} HW_SPARE_RO{i} ro (i=0..3)
  [31:0] hw_spare_ro{i} — Reserved for HW R&D
0xFF0 HW_SPARE_WPH
  [31:0] proc — Write pulse bit field: For bits 0 to 7: Wrting 1'b1 : Generates pulse interrupt to corresponding proc from MSS_CR5A. For bits 8 to 15: RESERVED
0xFF4 HW_SPARE_REC
  [n] hw_spare_rec{n} (n=0..31) — Reserved for HW R&D
0x1008 LOCK0_KICK0 — - KICK0 component
  [31:0] ?
0x100C LOCK0_KICK1 — - KICK1 component
  [31:0] ?
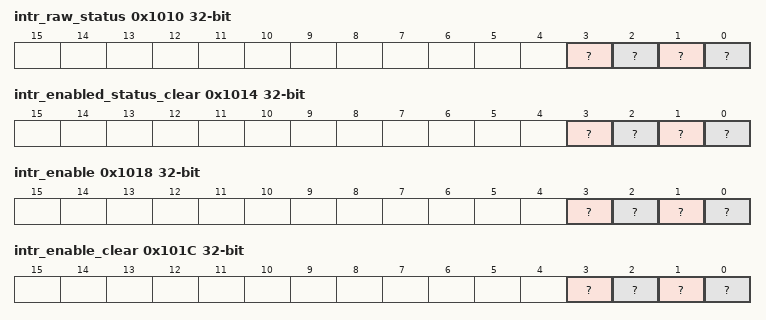
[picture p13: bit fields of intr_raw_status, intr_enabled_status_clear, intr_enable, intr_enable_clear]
0x1010 intr_raw_status — Interrupt Raw Status/Set Register
  [3] ? — Proxy0 access violation error. Raw status is read. Write a 1 to set the status. Writing a 0 has no effect.
  [2] ? — Kick access violation error. Raw status is read. Write a 1 to set the status. Writing a 0 has no effect.
  [1] ? — Addressing violation error. Raw status is read. Write a 1 to set the status. Writing a 0 has no effect.
  [0] ? — Protection violation error. Raw status is read. Write a 1 to set the status. Writing a 0 has no effect.
0x1014 intr_enabled_status_clear — Interrupt Enabled Status/Clear register
  [3] ? — Proxy0 access violation error. Enabled status is read. Write a 1 to clear the status. Writing a 0 has no effect.
  [2] ? — Kick access violation error. Enabled status is read. Write a 1 to clear the status. Writing a 0 has no effect.
  [1] ? — Addressing violation error. Enabled status is read. Write a 1 to clear the status. Writing a 0 has no effect.
  [0] ? — Protection violation error. Enabled status is read. Write a 1 to clear the status. Writing a 0 has no effect.
0x1018 intr_enable — Interrupt Enable register
  [3] ? — Proxy0 access violation error enable. Write a 1 to set the enable. Writing a 0 has no effect.
  [2] ? — Kick access violation error enable. Write a 1 to set the enable. Writing a 0 has no effect.
  [1] ? — Addressing violation error enable. Write a 1 to set the enable. Writing a 0 has no effect.
  [0] ? — Protection violation error enable. Write a 1 to set the enable. Writing a 0 has no effect.
0x101C intr_enable_clear — Interrupt Enable Clear register
  [3] ? — Proxy0 access violation error enable clear. Write a 1 to clear the enable. Writing a 0 has no effect.
  [2] ? — Kick access violation error enable clear. Write a 1 to clear the enable. Writing a 0 has no effect.
  [1] ? — Addressing violation error enable clear. Write a 1 to clear the enable. Writing a 0 has no effect.
  [0] ? — Protection violation error enable clear. Write a 1 to clear the enable. Writing a 0 has no effect.
0x1020 eoi
  [7:0] ? — EOI vector value. Write this with interrupt distribution value in the chip.
0x1024 fault_address ro
  [31:0] ? — Fault Address.
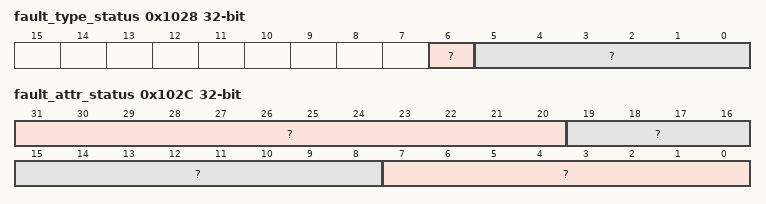
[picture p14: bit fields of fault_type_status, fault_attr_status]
0x1028 fault_type_status ro
  [6] ? — Non-secure access.
  [5:0] ? — Fault Type 10_0000 = Supervisor read fault - priv = 1 dir = 1 dtype != 1 01_0000 = Supervisor write fault - priv = 1 dir = 0 00_1000 = Supervisor execute fault - priv = 1 dir = 1 dtype = 1 00_0100 = User read fault - priv = 0 dir = 1 dtype = 1 00_0010 = User write fault - priv = 0 dir = 0 00_0001 = User execute fault - priv = 0 dir = 1 dtype = 1 00_0000 = No fault
0x102C fault_attr_status ro — Fault Attribute Status register
  [31:20] ? — XID.
  [19:8] ? — Route ID.
  [7:0] ? — Privilege ID.
0x1030 fault_clear wo
  [0] ? — Fault clear. Writing a 1 clears the current fault. Writing a 0 has no effect.
